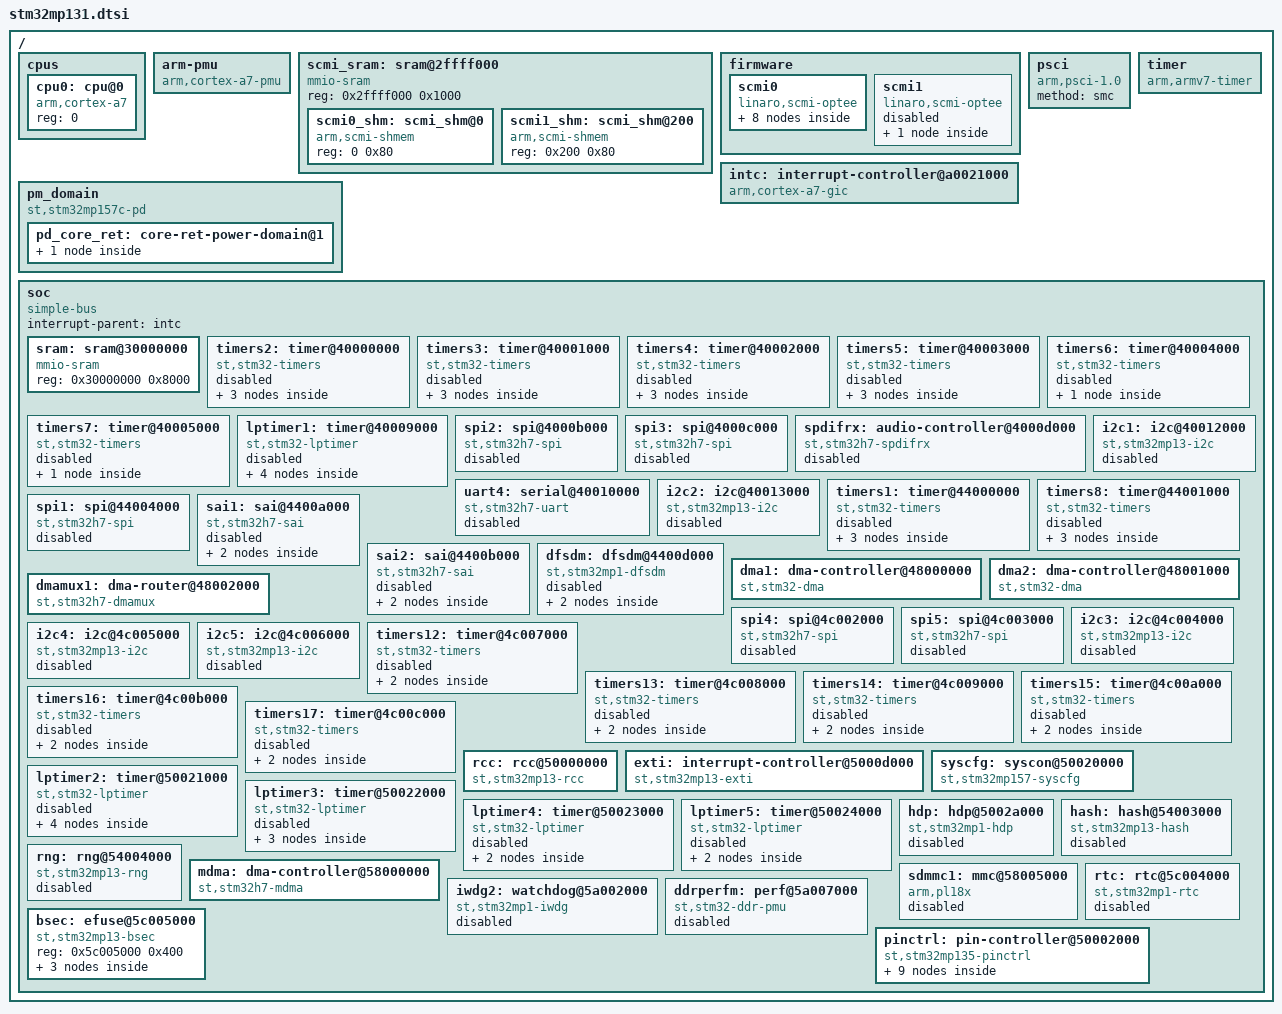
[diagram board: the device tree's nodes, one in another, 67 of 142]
// SPDX-License-Identifier: (GPL-2.0+ OR BSD-3-Clause)
/*
 * Copyright (C) STMicroelectronics 2021 - All Rights Reserved
 * Author: Alexandre Torgue <alexandre.torgue@foss.st.com> for STMicroelectronics.
 */
#include <dt-bindings/interrupt-controller/arm-gic.h>
#include <dt-bindings/clock/stm32mp13-clks.h>
#include <dt-bindings/reset/stm32mp13-resets.h>

/ {
	#address-cells = <1>;
	#size-cells = <1>;

	cpus {
		#address-cells = <1>;
		#size-cells = <0>;

		cpu0: cpu@0 {
			compatible = "arm,cortex-a7";
			device_type = "cpu";
			reg = <0>;
		};
	};

	arm-pmu {
		compatible = "arm,cortex-a7-pmu";
		interrupts = <GIC_SPI 133 IRQ_TYPE_LEVEL_HIGH>;
		interrupt-affinity = <&cpu0>;
		interrupt-parent = <&intc>;
	};

	scmi_sram: sram@2ffff000 {
		compatible = "mmio-sram";
		reg = <0x2ffff000 0x1000>;
		#address-cells = <1>;
		#size-cells = <1>;
		ranges = <0 0x2ffff000 0x1000>;

		scmi0_shm: scmi_shm@0 {
			compatible = "arm,scmi-shmem";
			reg = <0 0x80>;
		};

		scmi1_shm: scmi_shm@200 {
			compatible = "arm,scmi-shmem";
			reg = <0x200 0x80>;
		};
	};

	firmware {
		scmi0: scmi0 {
			compatible = "linaro,scmi-optee";
			#address-cells = <1>;
			#size-cells = <0>;
			linaro,channel-id = <0>;
			shmem = <&scmi0_shm>;

			scmi0_perf: protocol@13 {
				reg = <0x13>;
				#clock-cells = <1>;
			};

			scmi0_clk: protocol@14 {
				reg = <0x14>;
				#clock-cells = <1>;
			};

			scmi0_reset: protocol@16 {
				reg = <0x16>;
				#reset-cells = <1>;
			};

			scmi0_voltd: protocol@17 {
				reg = <0x17>;

				scmi0_regu: regulators {
					scmi_reg11: voltd-reg11 {
						voltd-name = "reg11";
						regulator-name = "reg11";
					};
					scmi_reg18: voltd-reg18 {
						voltd-name = "reg18";
						regulator-name = "reg18";
					};
					scmi_usb33: voltd-usb33 {
						voltd-name = "usb33";
						regulator-name = "usb33";
					};
				};
			};
		};

		scmi1: scmi1 {
			compatible = "linaro,scmi-optee";
			#address-cells = <1>;
			#size-cells = <0>;
			linaro,channel-id = <1>;
			shmem = <&scmi1_shm>;
			status = "disabled";

			scmi1_clk: protocol@14 {
				reg = <0x14>;
				#clock-cells = <1>;
			};
		};
	};

	intc: interrupt-controller@a0021000 {
		compatible = "arm,cortex-a7-gic";
		#interrupt-cells = <3>;
		interrupt-controller;
		reg = <0xa0021000 0x1000>,
		      <0xa0022000 0x2000>;
	};

	psci {
		compatible = "arm,psci-1.0";
		method = "smc";
	};

	timer {
		compatible = "arm,armv7-timer";
		interrupts = <GIC_PPI 13 (GIC_CPU_MASK_SIMPLE(4) | IRQ_TYPE_LEVEL_LOW)>,
			     <GIC_PPI 14 (GIC_CPU_MASK_SIMPLE(4) | IRQ_TYPE_LEVEL_LOW)>,
			     <GIC_PPI 11 (GIC_CPU_MASK_SIMPLE(4) | IRQ_TYPE_LEVEL_LOW)>,
			     <GIC_PPI 10 (GIC_CPU_MASK_SIMPLE(4) | IRQ_TYPE_LEVEL_LOW)>;
		interrupt-parent = <&intc>;
		always-on;
	};

	pm_domain {
		#address-cells = <1>;
		#size-cells = <0>;
		compatible = "st,stm32mp157c-pd";

		pd_core_ret: core-ret-power-domain@1 {
			#address-cells = <1>;
			#size-cells = <0>;
			reg = <1>;
			#power-domain-cells = <0>;
			label = "CORE-RETENTION";

			pd_core: core-power-domain@2 {
				reg = <2>;
				#power-domain-cells = <0>;
				label = "CORE";
			};
		};
	};

	soc {
		compatible = "simple-bus";
		#address-cells = <1>;
		#size-cells = <1>;
		interrupt-parent = <&intc>;
		ranges;

		sram: sram@30000000 {
			compatible = "mmio-sram";
			reg = <0x30000000 0x8000>;
			#address-cells = <1>;
			#size-cells = <1>;
			ranges = <0 0x30000000 0x8000>;
		};

		timers2: timer@40000000 {
			#address-cells = <1>;
			#size-cells = <0>;
			compatible = "st,stm32-timers";
			reg = <0x40000000 0x400>;
			clocks = <&rcc TIM2_K>;
			clock-names = "int";
			dmas = <&dmamux1 18 0x400 0x80000001>,
			       <&dmamux1 19 0x400 0x80000001>,
			       <&dmamux1 20 0x400 0x80000001>,
			       <&dmamux1 21 0x400 0x80000001>,
			       <&dmamux1 22 0x400 0x80000001>;
			dma-names = "ch1", "ch2", "ch3", "ch4", "up";
			status = "disabled";

			pwm {
				compatible = "st,stm32-pwm";
				#pwm-cells = <3>;
				status = "disabled";
			};

			timer@1 {
				compatible = "st,stm32h7-timer-trigger";
				reg = <1>;
				status = "disabled";
			};

			counter {
				compatible = "st,stm32-timer-counter";
				status = "disabled";
			};
		};

		timers3: timer@40001000 {
			#address-cells = <1>;
			#size-cells = <0>;
			compatible = "st,stm32-timers";
			reg = <0x40001000 0x400>;
			clocks = <&rcc TIM3_K>;
			clock-names = "int";
			dmas = <&dmamux1 23 0x400 0x80000001>,
			       <&dmamux1 24 0x400 0x80000001>,
			       <&dmamux1 25 0x400 0x80000001>,
			       <&dmamux1 26 0x400 0x80000001>,
			       <&dmamux1 27 0x400 0x80000001>,
			       <&dmamux1 28 0x400 0x80000001>;
			dma-names = "ch1", "ch2", "ch3", "ch4", "up", "trig";
			status = "disabled";

			pwm {
				compatible = "st,stm32-pwm";
				#pwm-cells = <3>;
				status = "disabled";
			};

			timer@2 {
				compatible = "st,stm32h7-timer-trigger";
				reg = <2>;
				status = "disabled";
			};

			counter {
				compatible = "st,stm32-timer-counter";
				status = "disabled";
			};
		};

		timers4: timer@40002000 {
			#address-cells = <1>;
			#size-cells = <0>;
			compatible = "st,stm32-timers";
			reg = <0x40002000 0x400>;
			clocks = <&rcc TIM4_K>;
			clock-names = "int";
			dmas = <&dmamux1 29 0x400 0x80000001>,
			       <&dmamux1 30 0x400 0x80000001>,
			       <&dmamux1 31 0x400 0x80000001>,
			       <&dmamux1 32 0x400 0x80000001>;
			dma-names = "ch1", "ch2", "ch3", "up";
			status = "disabled";

			pwm {
				compatible = "st,stm32-pwm";
				#pwm-cells = <3>;
				status = "disabled";
			};

			timer@3 {
				compatible = "st,stm32h7-timer-trigger";
				reg = <3>;
				status = "disabled";
			};

			counter {
				compatible = "st,stm32-timer-counter";
				status = "disabled";
			};
		};

		timers5: timer@40003000 {
			#address-cells = <1>;
			#size-cells = <0>;
			compatible = "st,stm32-timers";
			reg = <0x40003000 0x400>;
			clocks = <&rcc TIM5_K>;
			clock-names = "int";
			dmas = <&dmamux1 55 0x400 0x80000001>,
			       <&dmamux1 56 0x400 0x80000001>,
			       <&dmamux1 57 0x400 0x80000001>,
			       <&dmamux1 58 0x400 0x80000001>,
			       <&dmamux1 59 0x400 0x80000001>,
			       <&dmamux1 60 0x400 0x80000001>;
			dma-names = "ch1", "ch2", "ch3", "ch4", "up", "trig";
			status = "disabled";

			pwm {
				compatible = "st,stm32-pwm";
				#pwm-cells = <3>;
				status = "disabled";
			};

			timer@4 {
				compatible = "st,stm32h7-timer-trigger";
				reg = <4>;
				status = "disabled";
			};

			counter {
				compatible = "st,stm32-timer-counter";
				status = "disabled";
			};
		};

		timers6: timer@40004000 {
			#address-cells = <1>;
			#size-cells = <0>;
			compatible = "st,stm32-timers";
			reg = <0x40004000 0x400>;
			clocks = <&rcc TIM6_K>;
			clock-names = "int";
			dmas = <&dmamux1 69 0x400 0x80000001>;
			dma-names = "up";
			status = "disabled";

			timer@5 {
				compatible = "st,stm32h7-timer-trigger";
				reg = <5>;
				status = "disabled";
			};
		};

		timers7: timer@40005000 {
			#address-cells = <1>;
			#size-cells = <0>;
			compatible = "st,stm32-timers";
			reg = <0x40005000 0x400>;
			clocks = <&rcc TIM7_K>;
			clock-names = "int";
			dmas = <&dmamux1 70 0x400 0x80000001>;
			dma-names = "up";
			status = "disabled";

			timer@6 {
				compatible = "st,stm32h7-timer-trigger";
				reg = <6>;
				status = "disabled";
			};
		};

		lptimer1: timer@40009000 {
			#address-cells = <1>;
			#size-cells = <0>;
			compatible = "st,stm32-lptimer";
			reg = <0x40009000 0x400>;
			interrupts-extended = <&exti 47 IRQ_TYPE_LEVEL_HIGH>;
			clocks = <&rcc LPTIM1_K>;
			clock-names = "mux";
			power-domains = <&pd_core_ret>;
			wakeup-source;
			status = "disabled";

			pwm {
				compatible = "st,stm32-pwm-lp";
				#pwm-cells = <3>;
				status = "disabled";
			};

			trigger@0 {
				compatible = "st,stm32-lptimer-trigger";
				reg = <0>;
				status = "disabled";
			};

			counter {
				compatible = "st,stm32-lptimer-counter";
				status = "disabled";
			};

			timer {
				compatible = "st,stm32-lptimer-timer";
				status = "disabled";
			};
		};

		spi2: spi@4000b000 {
			#address-cells = <1>;
			#size-cells = <0>;
			compatible = "st,stm32h7-spi";
			reg = <0x4000b000 0x400>;
			interrupts = <GIC_SPI 37 IRQ_TYPE_LEVEL_HIGH>;
			clocks = <&rcc SPI2_K>;
			resets = <&rcc SPI2_R>;
			dmas = <&dmamux1 39 0x400 0x01>,
			       <&dmamux1 40 0x400 0x01>;
			dma-names = "rx", "tx";
			status = "disabled";
		};

		spi3: spi@4000c000 {
			#address-cells = <1>;
			#size-cells = <0>;
			compatible = "st,stm32h7-spi";
			reg = <0x4000c000 0x400>;
			interrupts = <GIC_SPI 52 IRQ_TYPE_LEVEL_HIGH>;
			clocks = <&rcc SPI3_K>;
			resets = <&rcc SPI3_R>;
			dmas = <&dmamux1 61 0x400 0x01>,
			       <&dmamux1 62 0x400 0x01>;
			dma-names = "rx", "tx";
			status = "disabled";
		};

		spdifrx: audio-controller@4000d000 {
			compatible = "st,stm32h7-spdifrx";
			#sound-dai-cells = <0>;
			reg = <0x4000d000 0x400>;
			clocks = <&rcc SPDIF_K>;
			clock-names = "kclk";
			interrupts = <GIC_SPI 95 IRQ_TYPE_LEVEL_HIGH>;
			dmas = <&dmamux1 93 0x400 0x01>,
			       <&dmamux1 94 0x400 0x01>;
			dma-names = "rx", "rx-ctrl";
			status = "disabled";
		};

		uart4: serial@40010000 {
			compatible = "st,stm32h7-uart";
			reg = <0x40010000 0x400>;
			interrupts = <GIC_SPI 53 IRQ_TYPE_LEVEL_HIGH>;
			clocks = <&rcc UART4_K>;
			resets = <&rcc UART4_R>;
			wakeup-source;
			power-domains = <&pd_core_ret>;
			status = "disabled";
		};

		i2c1: i2c@40012000 {
			compatible = "st,stm32mp13-i2c";
			reg = <0x40012000 0x400>;
			interrupt-names = "event", "error";
			interrupts-extended = <&exti 21 IRQ_TYPE_LEVEL_HIGH>,
					      <&intc GIC_SPI 33 IRQ_TYPE_LEVEL_HIGH>;
			clocks = <&rcc I2C1_K>;
			resets = <&rcc I2C1_R>;
			#address-cells = <1>;
			#size-cells = <0>;
			dmas = <&dmamux1 33 0x400 0x80000001>,
			       <&dmamux1 34 0x400 0x80000001>;
			dma-names = "rx", "tx";
			st,syscfg-fmp = <&syscfg 0x4 0x1>;
			i2c-analog-filter;
			status = "disabled";
		};

		i2c2: i2c@40013000 {
			compatible = "st,stm32mp13-i2c";
			reg = <0x40013000 0x400>;
			interrupt-names = "event", "error";
			interrupts-extended = <&exti 22 IRQ_TYPE_LEVEL_HIGH>,
					      <&intc GIC_SPI 35 IRQ_TYPE_LEVEL_HIGH>;
			clocks = <&rcc I2C2_K>;
			resets = <&rcc I2C2_R>;
			#address-cells = <1>;
			#size-cells = <0>;
			dmas = <&dmamux1 35 0x400 0x80000001>,
			       <&dmamux1 36 0x400 0x80000001>;
			dma-names = "rx", "tx";
			st,syscfg-fmp = <&syscfg 0x4 0x2>;
			i2c-analog-filter;
			status = "disabled";
		};

		timers1: timer@44000000 {
			#address-cells = <1>;
			#size-cells = <0>;
			compatible = "st,stm32-timers";
			reg = <0x44000000 0x400>;
			clocks = <&rcc TIM1_K>;
			clock-names = "int";
			dmas = <&dmamux1 11 0x400 0x80000001>,
			       <&dmamux1 12 0x400 0x80000001>,
			       <&dmamux1 13 0x400 0x80000001>,
			       <&dmamux1 14 0x400 0x80000001>,
			       <&dmamux1 15 0x400 0x80000001>,
			       <&dmamux1 16 0x400 0x80000001>,
			       <&dmamux1 17 0x400 0x80000001>;
			dma-names = "ch1", "ch2", "ch3", "ch4",
				    "up", "trig", "com";
			status = "disabled";

			pwm {
				compatible = "st,stm32-pwm";
				#pwm-cells = <3>;
				status = "disabled";
			};

			timer@0 {
				compatible = "st,stm32h7-timer-trigger";
				reg = <0>;
				status = "disabled";
			};

			counter {
				compatible = "st,stm32-timer-counter";
				status = "disabled";
			};
		};

		timers8: timer@44001000 {
			#address-cells = <1>;
			#size-cells = <0>;
			compatible = "st,stm32-timers";
			reg = <0x44001000 0x400>;
			clocks = <&rcc TIM8_K>;
			clock-names = "int";
			dmas = <&dmamux1 47 0x400 0x80000001>,
			       <&dmamux1 48 0x400 0x80000001>,
			       <&dmamux1 49 0x400 0x80000001>,
			       <&dmamux1 50 0x400 0x80000001>,
			       <&dmamux1 51 0x400 0x80000001>,
			       <&dmamux1 52 0x400 0x80000001>,
			       <&dmamux1 53 0x400 0x80000001>;
			dma-names = "ch1", "ch2", "ch3", "ch4",
				    "up", "trig", "com";
			status = "disabled";

			pwm {
				compatible = "st,stm32-pwm";
				#pwm-cells = <3>;
				status = "disabled";
			};

			timer@7 {
				compatible = "st,stm32h7-timer-trigger";
				reg = <7>;
				status = "disabled";
			};

			counter {
				compatible = "st,stm32-timer-counter";
				status = "disabled";
			};
		};

		spi1: spi@44004000 {
			#address-cells = <1>;
			#size-cells = <0>;
			compatible = "st,stm32h7-spi";
			reg = <0x44004000 0x400>;
			interrupts = <GIC_SPI 36 IRQ_TYPE_LEVEL_HIGH>;
			clocks = <&rcc SPI1_K>;
			resets = <&rcc SPI1_R>;
			dmas = <&dmamux1 37 0x400 0x01>,
			       <&dmamux1 38 0x400 0x01>;
			dma-names = "rx", "tx";
			status = "disabled";
		};


		sai1: sai@4400a000 {
			compatible = "st,stm32h7-sai";
			#address-cells = <1>;
			#size-cells = <1>;
			ranges = <0 0x4400a000 0x400>;
			reg = <0x4400a000 0x4>, <0x4400a3f0 0x10>;
			interrupts = <GIC_SPI 87 IRQ_TYPE_LEVEL_HIGH>;
			resets = <&rcc SAI1_R>;
			status = "disabled";

			sai1a: audio-controller@4400a004 {
				#sound-dai-cells = <0>;

				compatible = "st,stm32-sai-sub-a";
				reg = <0x4 0x20>;
				clocks = <&rcc SAI1_K>;
				clock-names = "sai_ck";
				dmas = <&dmamux1 87 0x400 0x01>;
				status = "disabled";
			};

			sai1b: audio-controller@4400a024 {
				#sound-dai-cells = <0>;
				compatible = "st,stm32-sai-sub-b";
				reg = <0x24 0x20>;
				clocks = <&rcc SAI1_K>;
				clock-names = "sai_ck";
				dmas = <&dmamux1 88 0x400 0x01>;
				status = "disabled";
			};
		};

		sai2: sai@4400b000 {
			compatible = "st,stm32h7-sai";
			#address-cells = <1>;
			#size-cells = <1>;
			ranges = <0 0x4400b000 0x400>;
			reg = <0x4400b000 0x4>, <0x4400b3f0 0x10>;
			interrupts = <GIC_SPI 90 IRQ_TYPE_LEVEL_HIGH>;
			resets = <&rcc SAI2_R>;
			status = "disabled";

			sai2a: audio-controller@4400b004 {
				#sound-dai-cells = <0>;
				compatible = "st,stm32-sai-sub-a";
				reg = <0x4 0x20>;
				clocks = <&rcc SAI2_K>;
				clock-names = "sai_ck";
				dmas = <&dmamux1 89 0x400 0x01>;
				status = "disabled";
			};

			sai2b: audio-controller@4400b024 {
				#sound-dai-cells = <0>;
				compatible = "st,stm32-sai-sub-b";
				reg = <0x24 0x20>;
				clocks = <&rcc SAI2_K>;
				clock-names = "sai_ck";
				dmas = <&dmamux1 90 0x400 0x01>;
				status = "disabled";
			};
		};

		dfsdm: dfsdm@4400d000 {
			compatible = "st,stm32mp1-dfsdm";
			reg = <0x4400d000 0x800>;
			clocks = <&rcc DFSDM_K>;
			clock-names = "dfsdm";
			#address-cells = <1>;
			#size-cells = <0>;
			status = "disabled";

			dfsdm0: filter@0 {
				compatible = "st,stm32-dfsdm-adc";
				#io-channel-cells = <1>;
				reg = <0>;
				interrupts = <GIC_SPI 140 IRQ_TYPE_LEVEL_HIGH>;
				dmas = <&dmamux1 101 0x400 0x01>;
				dma-names = "rx";
				status = "disabled";
			};

			dfsdm1: filter@1 {
				compatible = "st,stm32-dfsdm-adc";
				#io-channel-cells = <1>;
				reg = <1>;
				interrupts = <GIC_SPI 141 IRQ_TYPE_LEVEL_HIGH>;
				dmas = <&dmamux1 102 0x400 0x01>;
				dma-names = "rx";
				status = "disabled";
			};
		};

		dma1: dma-controller@48000000 {
			compatible = "st,stm32-dma";
			reg = <0x48000000 0x400>;
			interrupts = <GIC_SPI 11 IRQ_TYPE_LEVEL_HIGH>,
				     <GIC_SPI 12 IRQ_TYPE_LEVEL_HIGH>,
				     <GIC_SPI 13 IRQ_TYPE_LEVEL_HIGH>,
				     <GIC_SPI 14 IRQ_TYPE_LEVEL_HIGH>,
				     <GIC_SPI 15 IRQ_TYPE_LEVEL_HIGH>,
				     <GIC_SPI 16 IRQ_TYPE_LEVEL_HIGH>,
				     <GIC_SPI 17 IRQ_TYPE_LEVEL_HIGH>,
				     <GIC_SPI 48 IRQ_TYPE_LEVEL_HIGH>;
			clocks = <&rcc DMA1>;
			resets = <&rcc DMA1_R>;
			#dma-cells = <4>;
			st,mem2mem;
			dma-requests = <8>;
			dmas = <&mdma 0 0x3 0x1200000a 0x48000008 0x00000020 1>,
			       <&mdma 1 0x3 0x1200000a 0x48000008 0x00000800 1>,
			       <&mdma 2 0x3 0x1200000a 0x48000008 0x00200000 1>,
			       <&mdma 3 0x3 0x1200000a 0x48000008 0x08000000 1>,
			       <&mdma 4 0x3 0x1200000a 0x4800000C 0x00000020 1>,
			       <&mdma 5 0x3 0x1200000a 0x4800000C 0x00000800 1>,
			       <&mdma 6 0x3 0x1200000a 0x4800000C 0x00200000 1>,
			       <&mdma 7 0x3 0x1200000a 0x4800000C 0x08000000 1>;
			dma-names = "ch0", "ch1", "ch2", "ch3", "ch4", "ch5", "ch6", "ch7";
		};

		dma2: dma-controller@48001000 {
			compatible = "st,stm32-dma";
			reg = <0x48001000 0x400>;
			interrupts = <GIC_SPI 57 IRQ_TYPE_LEVEL_HIGH>,
				     <GIC_SPI 58 IRQ_TYPE_LEVEL_HIGH>,
				     <GIC_SPI 59 IRQ_TYPE_LEVEL_HIGH>,
				     <GIC_SPI 60 IRQ_TYPE_LEVEL_HIGH>,
				     <GIC_SPI 61 IRQ_TYPE_LEVEL_HIGH>,
				     <GIC_SPI 69 IRQ_TYPE_LEVEL_HIGH>,
				     <GIC_SPI 70 IRQ_TYPE_LEVEL_HIGH>,
				     <GIC_SPI 71 IRQ_TYPE_LEVEL_HIGH>;
			clocks = <&rcc DMA2>;
			resets = <&rcc DMA2_R>;
			#dma-cells = <4>;
			st,mem2mem;
			dma-requests = <8>;
			dmas = <&mdma 8 0x3 0x1200000a 0x48001008 0x00000020 1>,
			       <&mdma 9 0x3 0x1200000a 0x48001008 0x00000800 1>,
			       <&mdma 10 0x3 0x1200000a 0x48001008 0x00200000 1>,
			       <&mdma 11 0x3 0x1200000a 0x48001008 0x08000000 1>,
			       <&mdma 12 0x3 0x1200000a 0x4800100C 0x00000020 1>,
			       <&mdma 13 0x3 0x1200000a 0x4800100C 0x00000800 1>,
			       <&mdma 14 0x3 0x1200000a 0x4800100C 0x00200000 1>,
			       <&mdma 15 0x3 0x1200000a 0x4800100C 0x08000000 1>;
			dma-names = "ch0", "ch1", "ch2", "ch3", "ch4", "ch5", "ch6", "ch7";
		};

		dmamux1: dma-router@48002000 {
			compatible = "st,stm32h7-dmamux";
			reg = <0x48002000 0x40>;
			clocks = <&rcc DMAMUX1>;
			resets = <&rcc DMAMUX1_R>;
			#dma-cells = <3>;
			dma-masters = <&dma1 &dma2>;
			dma-requests = <128>;
			dma-channels = <16>;
		};

		spi4: spi@4c002000 {
			#address-cells = <1>;
			#size-cells = <0>;
			compatible = "st,stm32h7-spi";
			reg = <0x4c002000 0x400>;
			interrupts = <GIC_SPI 85 IRQ_TYPE_LEVEL_HIGH>;
			clocks = <&rcc SPI4_K>;
			resets = <&rcc SPI4_R>;
			dmas = <&dmamux1 83 0x400 0x01>,
			       <&dmamux1 84 0x400 0x01>;
			dma-names = "rx", "tx";
			status = "disabled";
		};

		spi5: spi@4c003000 {
			#address-cells = <1>;
			#size-cells = <0>;
			compatible = "st,stm32h7-spi";
			reg = <0x4c003000 0x400>;
			interrupts = <GIC_SPI 86 IRQ_TYPE_LEVEL_HIGH>;
			clocks = <&rcc SPI5_K>;
			resets = <&rcc SPI5_R>;
			dmas = <&dmamux1 85 0x400 0x01>,
			       <&dmamux1 86 0x400 0x01>;
			dma-names = "rx", "tx";
			status = "disabled";
		};

		i2c3: i2c@4c004000 {
			compatible = "st,stm32mp13-i2c";
			reg = <0x4c004000 0x400>;
			interrupt-names = "event", "error";
			interrupts-extended = <&exti 23 IRQ_TYPE_LEVEL_HIGH>,
					      <&intc GIC_SPI 74 IRQ_TYPE_LEVEL_HIGH>;
			clocks = <&rcc I2C3_K>;
			resets = <&rcc I2C3_R>;
			#address-cells = <1>;
			#size-cells = <0>;
			dmas = <&dmamux1 73 0x400 0x80000001>,
			       <&dmamux1 74 0x400 0x80000001>;
			dma-names = "rx", "tx";
			st,syscfg-fmp = <&syscfg 0x4 0x4>;
			i2c-analog-filter;
			status = "disabled";
		};

		i2c4: i2c@4c005000 {
			compatible = "st,stm32mp13-i2c";
			reg = <0x4c005000 0x400>;
			interrupt-names = "event", "error";
			interrupts-extended = <&exti 24 IRQ_TYPE_LEVEL_HIGH>,
					      <&intc GIC_SPI 94 IRQ_TYPE_LEVEL_HIGH>;
			clocks = <&rcc I2C4_K>;
			resets = <&rcc I2C4_R>;
			#address-cells = <1>;
			#size-cells = <0>;
			dmas = <&dmamux1 75 0x400 0x80000001>,
			       <&dmamux1 76 0x400 0x80000001>;
			dma-names = "rx", "tx";
			st,syscfg-fmp = <&syscfg 0x4 0x8>;
			i2c-analog-filter;
			status = "disabled";
		};

		i2c5: i2c@4c006000 {
			compatible = "st,stm32mp13-i2c";
			reg = <0x4c006000 0x400>;
			interrupt-names = "event", "error";
			interrupts-extended = <&exti 25 IRQ_TYPE_LEVEL_HIGH>,
					      <&intc GIC_SPI 115 IRQ_TYPE_LEVEL_HIGH>;
			clocks = <&rcc I2C5_K>;
			resets = <&rcc I2C5_R>;
			#address-cells = <1>;
			#size-cells = <0>;
			dmas = <&dmamux1 115 0x400 0x80000001>,
			       <&dmamux1 116 0x400 0x80000001>;
			dma-names = "rx", "tx";
			st,syscfg-fmp = <&syscfg 0x4 0x10>;
			i2c-analog-filter;
			status = "disabled";
		};

		timers12: timer@4c007000 {
			#address-cells = <1>;
			#size-cells = <0>;
			compatible = "st,stm32-timers";
			reg = <0x4c007000 0x400>;
			clocks = <&rcc TIM12_K>;
			clock-names = "int";
			status = "disabled";

			pwm {
				compatible = "st,stm32-pwm";
				#pwm-cells = <3>;
				status = "disabled";
			};

			timer@11 {
				compatible = "st,stm32h7-timer-trigger";
				reg = <11>;
				status = "disabled";
			};
		};

		timers13: timer@4c008000 {
			#address-cells = <1>;
			#size-cells = <0>;
			compatible = "st,stm32-timers";
			reg = <0x4c008000 0x400>;
			clocks = <&rcc TIM13_K>;
			clock-names = "int";
			status = "disabled";

			pwm {
				compatible = "st,stm32-pwm";
				#pwm-cells = <3>;
				status = "disabled";
			};

			timer@12 {
				compatible = "st,stm32h7-timer-trigger";
				reg = <12>;
				status = "disabled";
			};
		};

		timers14: timer@4c009000 {
			#address-cells = <1>;
			#size-cells = <0>;
			compatible = "st,stm32-timers";
			reg = <0x4c009000 0x400>;
			clocks = <&rcc TIM14_K>;
			clock-names = "int";
			status = "disabled";

			pwm {
				compatible = "st,stm32-pwm";
				#pwm-cells = <3>;
				status = "disabled";
			};

			timer@13 {
				compatible = "st,stm32h7-timer-trigger";
				reg = <13>;
				status = "disabled";
			};
		};

		timers15: timer@4c00a000 {
			#address-cells = <1>;
			#size-cells = <0>;
			compatible = "st,stm32-timers";
			reg = <0x4c00a000 0x400>;
			clocks = <&rcc TIM15_K>;
			clock-names = "int";
			dmas = <&dmamux1 105 0x400 0x80000001>,
			       <&dmamux1 106 0x400 0x80000001>,
			       <&dmamux1 107 0x400 0x80000001>,
			       <&dmamux1 108 0x400 0x80000001>;
			dma-names = "ch1", "up", "trig", "com";
			status = "disabled";

			pwm {
				compatible = "st,stm32-pwm";
				#pwm-cells = <3>;
				status = "disabled";
			};

			timer@14 {
				compatible = "st,stm32h7-timer-trigger";
				reg = <14>;
				status = "disabled";
			};
		};

		timers16: timer@4c00b000 {
			#address-cells = <1>;
			#size-cells = <0>;
			compatible = "st,stm32-timers";
			reg = <0x4c00b000 0x400>;
			clocks = <&rcc TIM16_K>;
			clock-names = "int";
			dmas = <&dmamux1 109 0x400 0x80000001>,
			       <&dmamux1 110 0x400 0x80000001>;
			dma-names = "ch1", "up";
			status = "disabled";

			pwm {
				compatible = "st,stm32-pwm";
				#pwm-cells = <3>;
				status = "disabled";
			};

			timer@15 {
				compatible = "st,stm32h7-timer-trigger";
				reg = <15>;
				status = "disabled";
			};
		};

		timers17: timer@4c00c000 {
			#address-cells = <1>;
			#size-cells = <0>;
			compatible = "st,stm32-timers";
			reg = <0x4c00c000 0x400>;
			clocks = <&rcc TIM17_K>;
			clock-names = "int";
			dmas = <&dmamux1 111 0x400 0x80000001>,
			       <&dmamux1 112 0x400 0x80000001>;
			dma-names = "ch1", "up";
			status = "disabled";

			pwm {
				compatible = "st,stm32-pwm";
				#pwm-cells = <3>;
				status = "disabled";
			};

			timer@16 {
				compatible = "st,stm32h7-timer-trigger";
				reg = <16>;
				status = "disabled";
			};
		};

		rcc: rcc@50000000 {
			compatible = "st,stm32mp13-rcc", "syscon";
			reg = <0x50000000 0x1000>;
			#clock-cells = <1>;
			#reset-cells = <1>;
			interrupts = <GIC_SPI 5 IRQ_TYPE_LEVEL_HIGH>;

			clock-names = "hse", "hsi", "csi", "lse", "lsi";
			clocks = <&scmi0_clk CK_SCMI0_HSE>,
				 <&scmi0_clk CK_SCMI0_HSI>,
				 <&scmi0_clk CK_SCMI0_CSI>,
				 <&scmi0_clk CK_SCMI0_LSE>,
				 <&scmi0_clk CK_SCMI0_LSI>;
		};

		exti: interrupt-controller@5000d000 {
			compatible = "st,stm32mp13-exti", "syscon";
			interrupt-controller;
			#interrupt-cells = <2>;
			reg = <0x5000d000 0x400>;
		};

		syscfg: syscon@50020000 {
			compatible = "st,stm32mp157-syscfg", "syscon";
			reg = <0x50020000 0x400>;
			clocks = <&rcc SYSCFG>;
		};

		lptimer2: timer@50021000 {
			#address-cells = <1>;
			#size-cells = <0>;
			compatible = "st,stm32-lptimer";
			reg = <0x50021000 0x400>;
			interrupts-extended = <&exti 48 IRQ_TYPE_LEVEL_HIGH>;
			clocks = <&rcc LPTIM2_K>;
			clock-names = "mux";
			power-domains = <&pd_core_ret>;
			wakeup-source;
			status = "disabled";

			pwm {
				compatible = "st,stm32-pwm-lp";
				#pwm-cells = <3>;
				status = "disabled";
			};

			trigger@1 {
				compatible = "st,stm32-lptimer-trigger";
				reg = <1>;
				status = "disabled";
			};

			counter {
				compatible = "st,stm32-lptimer-counter";
				status = "disabled";
			};

			timer {
				compatible = "st,stm32-lptimer-timer";
				status = "disabled";
			};
		};

		lptimer3: timer@50022000 {
			#address-cells = <1>;
			#size-cells = <0>;
			compatible = "st,stm32-lptimer";
			reg = <0x50022000 0x400>;
			interrupts-extended = <&exti 50 IRQ_TYPE_LEVEL_HIGH>;
			clocks = <&rcc LPTIM3_K>;
			clock-names = "mux";
			power-domains = <&pd_core_ret>;
			wakeup-source;
			status = "disabled";

			pwm {
				compatible = "st,stm32-pwm-lp";
				#pwm-cells = <3>;
				status = "disabled";
			};

			trigger@2 {
				compatible = "st,stm32-lptimer-trigger";
				reg = <2>;
				status = "disabled";
			};

			timer {
				compatible = "st,stm32-lptimer-timer";
				status = "disabled";
			};
		};

		lptimer4: timer@50023000 {
			compatible = "st,stm32-lptimer";
			reg = <0x50023000 0x400>;
			interrupts-extended = <&exti 52 IRQ_TYPE_LEVEL_HIGH>;
			clocks = <&rcc LPTIM4_K>;
			clock-names = "mux";
			power-domains = <&pd_core_ret>;
			wakeup-source;
			status = "disabled";

			pwm {
				compatible = "st,stm32-pwm-lp";
				#pwm-cells = <3>;
				status = "disabled";
			};

			timer {
				compatible = "st,stm32-lptimer-timer";
				status = "disabled";
			};
		};

		lptimer5: timer@50024000 {
			compatible = "st,stm32-lptimer";
			reg = <0x50024000 0x400>;
			interrupts-extended = <&exti 53 IRQ_TYPE_LEVEL_HIGH>;
			clocks = <&rcc LPTIM5_K>;
			clock-names = "mux";
			power-domains = <&pd_core_ret>;
			wakeup-source;
			status = "disabled";

			pwm {
				compatible = "st,stm32-pwm-lp";
				#pwm-cells = <3>;
				status = "disabled";
			};

			timer {
				compatible = "st,stm32-lptimer-timer";
				status = "disabled";
			};
		};

		hdp: hdp@5002a000 {
			compatible = "st,stm32mp1-hdp";
			reg = <0x5002a000 0x400>;
			clocks = <&rcc HDP>;
			clock-names = "hdp";
			status = "disabled";
		};

		hash: hash@54003000 {
			compatible = "st,stm32mp13-hash";
			reg = <0x54003000 0x400>;
			interrupts = <GIC_SPI 81 IRQ_TYPE_LEVEL_HIGH>;
			clocks = <&rcc HASH1>;
			resets = <&rcc HASH1_R>;
			dmas = <&mdma 30 0x2 0x1000A02 0x0 0x0 0x0>;
			dma-names = "in";
			status = "disabled";
		};

		rng: rng@54004000 {
			compatible = "st,stm32mp13-rng";
			reg = <0x54004000 0x400>;
			clocks = <&rcc RNG1_K>;
			resets = <&rcc RNG1_R>;
			status = "disabled";
		};

		mdma: dma-controller@58000000 {
			compatible = "st,stm32h7-mdma";
			reg = <0x58000000 0x1000>;
			interrupts = <GIC_SPI 107 IRQ_TYPE_LEVEL_HIGH>;
			clocks = <&rcc MDMA>;
			#dma-cells = <6>;
			dma-channels = <32>;
			dma-requests = <48>;
		};

		sdmmc1: mmc@58005000 {
			compatible = "arm,pl18x", "arm,primecell";
			arm,primecell-periphid = <0x00253180>;
			reg = <0x58005000 0x1000>, <0x58006000 0x1000>;
			interrupts = <GIC_SPI 50 IRQ_TYPE_LEVEL_HIGH>;
			interrupt-names = "cmd_irq";
			clocks = <&rcc SDMMC1_K>;
			clock-names = "apb_pclk";
			resets = <&rcc SDMMC1_R>;
			cap-sd-highspeed;
			cap-mmc-highspeed;
			max-frequency = <120000000>;
			status = "disabled";
		};

		iwdg2: watchdog@5a002000 {
			compatible = "st,stm32mp1-iwdg";
			reg = <0x5a002000 0x400>;
			clocks = <&rcc IWDG2>, <&scmi0_clk CK_SCMI0_LSI>;
			clock-names = "pclk", "lsi";
			status = "disabled";
		};

		ddrperfm: perf@5a007000 {
			compatible = "st,stm32-ddr-pmu";
			reg = <0x5a007000 0x400>;
			clocks = <&rcc DDRPERFM>;
			resets = <&rcc DDRPERFM_R>;
			status = "disabled";
		};

		rtc: rtc@5c004000 {
			compatible = "st,stm32mp1-rtc";
			reg = <0x5c004000 0x400>;
			clocks = <&scmi0_clk CK_SCMI0_RTCAPB>,
				 <&scmi0_clk CK_SCMI0_RTC>;
			clock-names = "pclk", "rtc_ck";
			interrupts-extended = <&exti 19 IRQ_TYPE_LEVEL_HIGH>;
			status = "disabled";
		};

		bsec: efuse@5c005000 {
			compatible = "st,stm32mp13-bsec";
			reg = <0x5c005000 0x400>;
			#address-cells = <1>;
			#size-cells = <1>;

			part_number_otp: part_number_otp@4 {
				reg = <0x4 0x2>;
			};
			ts_cal1: calib@5c {
				reg = <0x5c 0x2>;
			};
			ts_cal2: calib@5e {
				reg = <0x5e 0x2>;
			};
		};

		/*
		 * Break node order to solve dependency probe issue between
		 * pinctrl and exti.
		 */
		pinctrl: pin-controller@50002000 {
			#address-cells = <1>;
			#size-cells = <1>;
			compatible = "st,stm32mp135-pinctrl";
			ranges = <0 0x50002000 0x8400>;
			interrupt-parent = <&exti>;
			st,syscfg = <&exti 0x60 0xff>;
			pins-are-numbered;

			gpioa: gpio@50002000 {
				gpio-controller;
				#gpio-cells = <2>;
				interrupt-controller;
				#interrupt-cells = <2>;
				reg = <0x0 0x400>;
				clocks = <&rcc GPIOA>;
				st,bank-name = "GPIOA";
				ngpios = <16>;
				gpio-ranges = <&pinctrl 0 0 16>;
			};

			gpiob: gpio@50003000 {
				gpio-controller;
				#gpio-cells = <2>;
				interrupt-controller;
				#interrupt-cells = <2>;
				reg = <0x1000 0x400>;
				clocks = <&rcc GPIOB>;
				st,bank-name = "GPIOB";
				ngpios = <16>;
				gpio-ranges = <&pinctrl 0 16 16>;
			};

			gpioc: gpio@50004000 {
				gpio-controller;
				#gpio-cells = <2>;
				interrupt-controller;
				#interrupt-cells = <2>;
				reg = <0x2000 0x400>;
				clocks = <&rcc GPIOC>;
				st,bank-name = "GPIOC";
				ngpios = <16>;
				gpio-ranges = <&pinctrl 0 32 16>;
			};

			gpiod: gpio@50005000 {
				gpio-controller;
				#gpio-cells = <2>;
				interrupt-controller;
				#interrupt-cells = <2>;
				reg = <0x3000 0x400>;
				clocks = <&rcc GPIOD>;
				st,bank-name = "GPIOD";
				ngpios = <16>;
				gpio-ranges = <&pinctrl 0 48 16>;
			};

			gpioe: gpio@50006000 {
				gpio-controller;
				#gpio-cells = <2>;
				interrupt-controller;
				#interrupt-cells = <2>;
				reg = <0x4000 0x400>;
				clocks = <&rcc GPIOE>;
				st,bank-name = "GPIOE";
				ngpios = <16>;
				gpio-ranges = <&pinctrl 0 64 16>;
			};

			gpiof: gpio@50007000 {
				gpio-controller;
				#gpio-cells = <2>;
				interrupt-controller;
				#interrupt-cells = <2>;
				reg = <0x5000 0x400>;
				clocks = <&rcc GPIOF>;
				st,bank-name = "GPIOF";
				ngpios = <16>;
				gpio-ranges = <&pinctrl 0 80 16>;
			};

			gpiog: gpio@50008000 {
				gpio-controller;
				#gpio-cells = <2>;
				interrupt-controller;
				#interrupt-cells = <2>;
				reg = <0x6000 0x400>;
				clocks = <&rcc GPIOG>;
				st,bank-name = "GPIOG";
				ngpios = <16>;
				gpio-ranges = <&pinctrl 0 96 16>;
			};

			gpioh: gpio@50009000 {
				gpio-controller;
				#gpio-cells = <2>;
				interrupt-controller;
				#interrupt-cells = <2>;
				reg = <0x7000 0x400>;
				clocks = <&rcc GPIOH>;
				st,bank-name = "GPIOH";
				ngpios = <15>;
				gpio-ranges = <&pinctrl 0 112 15>;
			};

			gpioi: gpio@5000a000 {
				gpio-controller;
				#gpio-cells = <2>;
				interrupt-controller;
				#interrupt-cells = <2>;
				reg = <0x8000 0x400>;
				clocks = <&rcc GPIOI>;
				st,bank-name = "GPIOI";
				ngpios = <8>;
				gpio-ranges = <&pinctrl 0 128 8>;
			};
		};
	};
};
